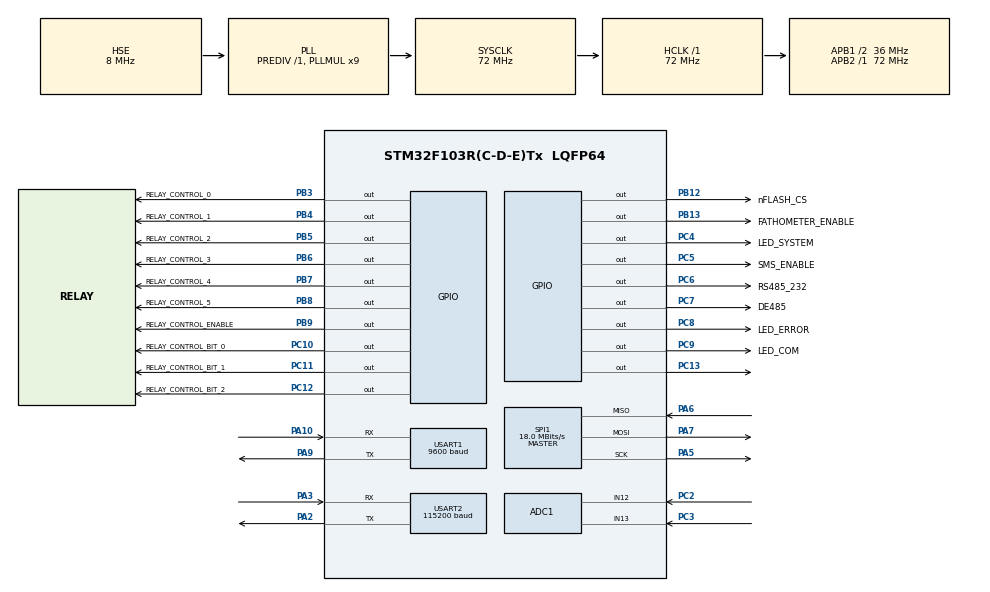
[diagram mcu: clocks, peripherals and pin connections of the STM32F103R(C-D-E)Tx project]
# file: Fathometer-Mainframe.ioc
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ADC1.Channel-0\#ChannelRegularConversion=ADC_CHANNEL_12
ADC1.Channel-1\#ChannelRegularConversion=ADC_CHANNEL_13
ADC1.ContinuousConvMode=ENABLE
ADC1.NbrOfConversion=2
ADC1.NbrOfConversionFlag=1
ADC1.Rank-0\#ChannelRegularConversion=1
ADC1.Rank-1\#ChannelRegularConversion=2
ADC1.SamplingTime-0\#ChannelRegularConversion=ADC_SAMPLETIME_239CYCLES_5
ADC1.SamplingTime-1\#ChannelRegularConversion=ADC_SAMPLETIME_239CYCLES_5
ADC1.master=1
Dma.ADC1.0.Direction=DMA_PERIPH_TO_MEMORY
Dma.ADC1.0.Instance=DMA1_Channel1
Dma.ADC1.0.MemDataAlignment=DMA_MDATAALIGN_HALFWORD
Dma.ADC1.0.MemInc=DMA_MINC_ENABLE
Dma.ADC1.0.Mode=DMA_CIRCULAR
Dma.ADC1.0.PeriphDataAlignment=DMA_PDATAALIGN_HALFWORD
Dma.ADC1.0.PeriphInc=DMA_PINC_DISABLE
Dma.ADC1.0.Priority=DMA_PRIORITY_LOW
Dma.Request0=ADC1
Dma.Request1=SPI1_TX
Dma.Request2=SPI1_RX
Dma.Request3=USART1_RX
Dma.Request4=USART1_TX
Dma.Request5=USART2_RX
Dma.Request6=USART2_TX
Dma.SPI1_RX.2.Direction=DMA_PERIPH_TO_MEMORY
Dma.SPI1_RX.2.Instance=DMA1_Channel2
Dma.SPI1_RX.2.MemDataAlignment=DMA_MDATAALIGN_BYTE
Dma.SPI1_RX.2.MemInc=DMA_MINC_ENABLE
Dma.SPI1_RX.2.Mode=DMA_NORMAL
Dma.SPI1_RX.2.PeriphDataAlignment=DMA_PDATAALIGN_BYTE
Dma.SPI1_RX.2.PeriphInc=DMA_PINC_DISABLE
Dma.SPI1_RX.2.Priority=DMA_PRIORITY_LOW
Dma.SPI1_TX.1.Direction=DMA_MEMORY_TO_PERIPH
Dma.SPI1_TX.1.Instance=DMA1_Channel3
Dma.SPI1_TX.1.MemDataAlignment=DMA_MDATAALIGN_BYTE
Dma.SPI1_TX.1.MemInc=DMA_MINC_ENABLE
Dma.SPI1_TX.1.Mode=DMA_NORMAL
Dma.SPI1_TX.1.PeriphDataAlignment=DMA_PDATAALIGN_BYTE
Dma.SPI1_TX.1.PeriphInc=DMA_PINC_DISABLE
Dma.SPI1_TX.1.Priority=DMA_PRIORITY_LOW
Dma.USART1_RX.3.Direction=DMA_PERIPH_TO_MEMORY
Dma.USART1_RX.3.Instance=DMA1_Channel5
Dma.USART1_RX.3.MemDataAlignment=DMA_MDATAALIGN_BYTE
Dma.USART1_RX.3.MemInc=DMA_MINC_ENABLE
Dma.USART1_RX.3.Mode=DMA_NORMAL
Dma.USART1_RX.3.PeriphDataAlignment=DMA_PDATAALIGN_BYTE
Dma.USART1_RX.3.PeriphInc=DMA_PINC_DISABLE
Dma.USART1_RX.3.Priority=DMA_PRIORITY_HIGH
Dma.USART1_TX.4.Direction=DMA_MEMORY_TO_PERIPH
Dma.USART1_TX.4.Instance=DMA1_Channel4
Dma.USART1_TX.4.MemDataAlignment=DMA_MDATAALIGN_BYTE
Dma.USART1_TX.4.MemInc=DMA_MINC_ENABLE
Dma.USART1_TX.4.Mode=DMA_NORMAL
Dma.USART1_TX.4.PeriphDataAlignment=DMA_PDATAALIGN_BYTE
Dma.USART1_TX.4.PeriphInc=DMA_PINC_DISABLE
Dma.USART1_TX.4.Priority=DMA_PRIORITY_LOW
Dma.USART2_RX.5.Direction=DMA_PERIPH_TO_MEMORY
Dma.USART2_RX.5.Instance=DMA1_Channel6
Dma.USART2_RX.5.MemDataAlignment=DMA_MDATAALIGN_BYTE
Dma.USART2_RX.5.MemInc=DMA_MINC_ENABLE
Dma.USART2_RX.5.Mode=DMA_NORMAL
Dma.USART2_RX.5.PeriphDataAlignment=DMA_PDATAALIGN_BYTE
Dma.USART2_RX.5.PeriphInc=DMA_PINC_DISABLE
Dma.USART2_RX.5.Priority=DMA_PRIORITY_LOW
Dma.USART2_TX.6.Direction=DMA_MEMORY_TO_PERIPH
Dma.USART2_TX.6.Instance=DMA1_Channel7
Dma.USART2_TX.6.MemDataAlignment=DMA_MDATAALIGN_BYTE
Dma.USART2_TX.6.MemInc=DMA_MINC_ENABLE
Dma.USART2_TX.6.Mode=DMA_NORMAL
Dma.USART2_TX.6.PeriphDataAlignment=DMA_PDATAALIGN_BYTE
Dma.USART2_TX.6.PeriphInc=DMA_PINC_DISABLE
Dma.USART2_TX.6.Priority=DMA_PRIORITY_LOW
FREERTOS.Events01=serialCommandEvent,Dynamic,NULL
FREERTOS.Tasks01=mainTask,24,1024,osMainEntry,Default,NULL,Dynamic,NULL,NULL;serialProcess,48,2048,serialCommandProcess,Default,NULL,Dynamic,NULL,NULL
FREERTOS.Timers01=heartbeatTimer,heartbeatCallback,osTimerPeriodic,Default,NULL,Dynamic,NULL
FREERTOS.configTICK_RATE_HZ=100
FREERTOS.configTOTAL_HEAP_SIZE=20480
FREERTOS.configUSE_NEWLIB_REENTRANT=1
IWDG.Prescaler=IWDG_PRESCALER_256
Mcu.Family=STM32F1
Mcu.Name=STM32F103R(C-D-E)Tx
Mcu.Package=LQFP64
NVIC.DMA1_Channel1_IRQn=true\:5\:0\:false\:false\:true\:true\:false\:true\:true
NVIC.DMA1_Channel2_IRQn=true\:5\:0\:false\:false\:true\:true\:false\:true\:true
NVIC.DMA1_Channel3_IRQn=true\:5\:0\:false\:false\:true\:true\:false\:true\:true
NVIC.DMA1_Channel4_IRQn=true\:5\:0\:false\:false\:true\:true\:false\:true\:true
NVIC.DMA1_Channel5_IRQn=true\:5\:0\:false\:false\:true\:true\:false\:true\:true
NVIC.DMA1_Channel6_IRQn=true\:5\:0\:false\:false\:true\:true\:false\:true\:true
NVIC.DMA1_Channel7_IRQn=true\:5\:0\:false\:false\:true\:true\:false\:true\:true
NVIC.PriorityGroup=NVIC_PRIORITYGROUP_4
NVIC.TIM6_IRQn=true\:15\:0\:false\:false\:true\:false\:false\:true\:true
NVIC.TimeBase=TIM6_IRQn
NVIC.TimeBaseIP=TIM6
NVIC.USART1_IRQn=true\:5\:0\:false\:false\:true\:true\:true\:true\:true
NVIC.USART2_IRQn=true\:5\:0\:false\:false\:true\:true\:true\:true\:true
PA10.GPIO_PuPd=GPIO_PULLUP
PA10.Mode=Asynchronous
PA10.Signal=USART1_RX
PA13.Mode=Serial_Wire
PA13.Signal=SYS_JTMS-SWDIO
PA14.Mode=Serial_Wire
PA14.Signal=SYS_JTCK-SWCLK
PA2.Mode=Asynchronous
PA2.Signal=USART2_TX
PA3.GPIO_PuPd=GPIO_PULLUP
PA3.Mode=Asynchronous
PA3.Signal=USART2_RX
PA5.Mode=Full_Duplex_Master
PA5.Signal=SPI1_SCK
PA6.Mode=Full_Duplex_Master
PA6.Signal=SPI1_MISO
PA7.Mode=Full_Duplex_Master
PA7.Signal=SPI1_MOSI
PA9.Mode=Asynchronous
PA9.Signal=USART1_TX
PB12.GPIO_Label=nFLASH_CS
PB12.Signal=GPIO_Output
PB13.GPIO_Label=FATHOMETER_ENABLE
PB13.Signal=GPIO_Output
PB3.GPIO_Label=RELAY_CONTROL_0
PB3.Signal=GPIO_Output
PB4.GPIO_Label=RELAY_CONTROL_1
PB4.Signal=GPIO_Output
PB5.GPIO_Label=RELAY_CONTROL_2
PB5.Signal=GPIO_Output
PB6.GPIO_Label=RELAY_CONTROL_3
PB6.Signal=GPIO_Output
PB7.GPIO_Label=RELAY_CONTROL_4
PB7.Signal=GPIO_Output
PB8.GPIO_Label=RELAY_CONTROL_5
PB8.Signal=GPIO_Output
PB9.GPIO_Label=RELAY_CONTROL_ENABLE
PB9.Signal=GPIO_Output
PC10.GPIO_Label=RELAY_CONTROL_BIT_0
PC10.Signal=GPIO_Output
PC11.GPIO_Label=RELAY_CONTROL_BIT_1
PC11.Signal=GPIO_Output
PC12.GPIO_Label=RELAY_CONTROL_BIT_2
PC12.Signal=GPIO_Output
PC13-TAMPER-RTC.GPIO_PuPd=GPIO_NOPULL
PC13-TAMPER-RTC.Signal=GPIO_Output
PC14-OSC32_IN.Mode=LSE-External-Oscillator
PC14-OSC32_IN.Signal=RCC_OSC32_IN
PC15-OSC32_OUT.Mode=LSE-External-Oscillator
PC15-OSC32_OUT.Signal=RCC_OSC32_OUT
PC2.Signal=ADCx_IN12
PC3.Signal=ADCx_IN13
PC4.GPIO_Label=LED_SYSTEM
PC4.Signal=GPIO_Output
PC5.GPIO_Label=SMS_ENABLE
PC5.Signal=GPIO_Output
PC6.GPIO_Label=RS485_232
PC6.PinState=GPIO_PIN_SET
PC6.Signal=GPIO_Output
PC7.GPIO_Label=DE485
PC7.Signal=GPIO_Output
PC8.GPIO_Label=LED_ERROR
PC8.Signal=GPIO_Output
PC9.GPIO_Label=LED_COM
PC9.Signal=GPIO_Output
PD0-OSC_IN.Mode=HSE-External-Oscillator
PD0-OSC_IN.Signal=RCC_OSC_IN
PD1-OSC_OUT.Mode=HSE-External-Oscillator
PD1-OSC_OUT.Signal=RCC_OSC_OUT
ProjectManager.HeapSize=0x200
ProjectManager.StackSize=0x400
ProjectManager.TargetToolchain=STM32CubeIDE
RCC.ADCPresc=RCC_ADCPCLK2_DIV6
RCC.AHBFreq_Value=72000000
RCC.APB1CLKDivider=RCC_HCLK_DIV2
RCC.APB1Freq_Value=36000000
RCC.APB1TimFreq_Value=72000000
RCC.APB2Freq_Value=72000000
RCC.APB2TimFreq_Value=72000000
RCC.HCLKFreq_Value=72000000
RCC.PLLMUL=RCC_PLL_MUL9
RCC.PLLSourceVirtual=RCC_PLLSOURCE_HSE
RCC.RTCClockSelection=RCC_RTCCLKSOURCE_LSE
RCC.SYSCLKFreq_VALUE=72000000
RCC.SYSCLKSource=RCC_SYSCLKSOURCE_PLLCLK
RCC.USBFreq_Value=72000000
RTC.Year=23
SH.ADCx_IN12.0=ADC1_IN12,IN12
SH.ADCx_IN13.0=ADC1_IN13,IN13
SPI1.BaudRatePrescaler=SPI_BAUDRATEPRESCALER_4
SPI1.CalculateBaudRate=18.0 MBits/s
SPI1.Direction=SPI_DIRECTION_2LINES
SPI1.Mode=SPI_MODE_MASTER
SPI1.VirtualType=VM_MASTER
USART1.BaudRate=9600
USART1.VirtualMode=VM_ASYNC
USART2.BaudRate=115200
USART2.VirtualMode=VM_ASYNC
VP_CRC_VS_CRC.Mode=CRC_Activate
VP_FREERTOS_VS_CMSIS_V2.Mode=CMSIS_V2
VP_IWDG_VS_IWDG.Mode=IWDG_Activate
VP_RTC_VS_RTC_Activate.Mode=RTC_Enabled
VP_RTC_VS_RTC_Calendar.Mode=RTC_Calendar
VP_SYS_VS_tim6.Mode=TIM6
board=custom

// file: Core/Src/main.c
/* USER CODE BEGIN Header */
/**
  ******************************************************************************
  * @file           : main.c
  * @brief          : Main program body
  ******************************************************************************
  * @attention
  *
  * Copyright (c) 2022 STMicroelectronics.
  * All rights reserved.
  *
  * This software is licensed under terms that can be found in the LICENSE file
  * in the root directory of this software component.
  * If no LICENSE file comes with this software, it is provided AS-IS.
  *
  ******************************************************************************
  */
/* USER CODE END Header */
#include "main.h"
#include "cmsis_os.h"
#include "adc.h"
#include "crc.h"
#include "dma.h"
#include "iwdg.h"
#include "rtc.h"
#include "spi.h"
#include "usart.h"
#include "gpio.h"

void SystemClock_Config(void);
void MX_FREERTOS_Init(void);

int main(void)
{

  /* MCU Configuration--------------------------------------------------------*/

  /* Reset of all peripherals, Initializes the Flash interface and the Systick. */
  HAL_Init();

  /* Configure the system clock */
  SystemClock_Config();

  /* Initialize all configured peripherals */
  MX_GPIO_Init();
  MX_DMA_Init();
  MX_RTC_Init();
  MX_ADC1_Init();
  MX_USART1_UART_Init();
  MX_USART2_UART_Init();
  MX_SPI1_Init();
  MX_CRC_Init();
  MX_IWDG_Init();

  /* Init scheduler */
  osKernelInitialize();  /* Call init function for freertos objects (in freertos.c) */
  MX_FREERTOS_Init();

  /* Start scheduler */
  osKernelStart();

  /* We should never get here as control is now taken by the scheduler */
  /* Infinite loop */
  while (1)
  {

  }
}

void SystemClock_Config(void)
{
  RCC_OscInitTypeDef RCC_OscInitStruct = {0};
  RCC_ClkInitTypeDef RCC_ClkInitStruct = {0};
  RCC_PeriphCLKInitTypeDef PeriphClkInit = {0};

  /** Initializes the RCC Oscillators according to the specified parameters
  * in the RCC_OscInitTypeDef structure.
  */
  RCC_OscInitStruct.OscillatorType = RCC_OSCILLATORTYPE_LSI|RCC_OSCILLATORTYPE_HSE
                              |RCC_OSCILLATORTYPE_LSE;
  RCC_OscInitStruct.HSEState = RCC_HSE_ON;
  RCC_OscInitStruct.HSEPredivValue = RCC_HSE_PREDIV_DIV1;
  RCC_OscInitStruct.LSEState = RCC_LSE_ON;
  RCC_OscInitStruct.HSIState = RCC_HSI_ON;
  RCC_OscInitStruct.LSIState = RCC_LSI_ON;
  RCC_OscInitStruct.PLL.PLLState = RCC_PLL_ON;
  RCC_OscInitStruct.PLL.PLLSource = RCC_PLLSOURCE_HSE;
  RCC_OscInitStruct.PLL.PLLMUL = RCC_PLL_MUL9;
  if (HAL_RCC_OscConfig(&RCC_OscInitStruct) != HAL_OK)
  {
    Error_Handler();
  }

  /** Initializes the CPU, AHB and APB buses clocks
  */
  RCC_ClkInitStruct.ClockType = RCC_CLOCKTYPE_HCLK|RCC_CLOCKTYPE_SYSCLK
                              |RCC_CLOCKTYPE_PCLK1|RCC_CLOCKTYPE_PCLK2;
  RCC_ClkInitStruct.SYSCLKSource = RCC_SYSCLKSOURCE_PLLCLK;
  RCC_ClkInitStruct.AHBCLKDivider = RCC_SYSCLK_DIV1;
  RCC_ClkInitStruct.APB1CLKDivider = RCC_HCLK_DIV2;
  RCC_ClkInitStruct.APB2CLKDivider = RCC_HCLK_DIV1;

  if (HAL_RCC_ClockConfig(&RCC_ClkInitStruct, FLASH_LATENCY_2) != HAL_OK)
  {
    Error_Handler();
  }
  PeriphClkInit.PeriphClockSelection = RCC_PERIPHCLK_RTC|RCC_PERIPHCLK_ADC;
  PeriphClkInit.RTCClockSelection = RCC_RTCCLKSOURCE_LSE;
  PeriphClkInit.AdcClockSelection = RCC_ADCPCLK2_DIV6;
  if (HAL_RCCEx_PeriphCLKConfig(&PeriphClkInit) != HAL_OK)
  {
    Error_Handler();
  }
}

void HAL_TIM_PeriodElapsedCallback(TIM_HandleTypeDef *htim)
{
  if (htim->Instance == TIM6) {
    HAL_IncTick();
  }
}

void Error_Handler(void)
{
  __disable_irq();
  while (1)
  {
  }
}

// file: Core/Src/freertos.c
/* USER CODE BEGIN Header */
/**
  ******************************************************************************
  * File Name          : freertos.c
  * Description        : Code for freertos applications
  ******************************************************************************
  * @attention
  *
  * Copyright (c) 2022 STMicroelectronics.
  * All rights reserved.
  *
  * This software is licensed under terms that can be found in the LICENSE file
  * in the root directory of this software component.
  * If no LICENSE file comes with this software, it is provided AS-IS.
  *
  ******************************************************************************
  */
/* USER CODE END Header */

#include "FreeRTOS.h"
#include "task.h"
#include "main.h"
#include "cmsis_os.h"

/* USER CODE BEGIN Includes */
#include "serial_feedback_define.h"
#include "flash.h"
/* USER CODE END Includes */

/* USER CODE BEGIN PTD */
union G_FLASH_DS {
    int intAccess[0x400];
    float floatAccess[0x400];
    uint32_t wordAccess[0x400];
    uint8_t byteAccess[0x1000];
};
union G_TASK_DS {
    int intAccess[13];
    float floatAccess[13];
    uint32_t wordAccess[13];
    uint8_t byteAccess[52];
};
/* USER CODE END PTD */

/* USER CODE BEGIN PD */
extern IWDG_HandleTypeDef hiwdg;
extern UART_HandleTypeDef huart1;
extern UART_HandleTypeDef huart2;
extern DMA_HandleTypeDef hdma_usart1_rx;
extern DMA_HandleTypeDef hdma_usart2_rx;
extern ADC_HandleTypeDef hadc1;
extern DMA_HandleTypeDef hdma_adc1;
extern RTC_HandleTypeDef hrtc;
extern CRC_HandleTypeDef hcrc;
/* USER CODE END PD */

/* USER CODE BEGIN PM */
#define RX_BUFFER_SIZE          100
#define RX_MAIN_BUFFER_SIZE     200

/* StatusReg flag define */
#define modeFlagA               31
#define modeFlagTransparent     30
#define ippFlag                 29
#define taskFlag                28
#define fathometerStatFlag1     27
#define fathometerStatFlag2     26
#define fathometerStatFlag3     25
#define fathometerStatFlag4     24
#define fathometerStatFlag5     23
#define fathometerStatFlag6     22
#define fathometerDataReadyFlag 21
#define flashDataPointerFlag    20
#define uplinkTimeoutFlag       19
#define maintenanceFlag         17
#define voltageFlag             16

/* Config address define */
#define SERIAL_NUMBER_ADDR      0x0807F000
#define BAUD_RATE_ADDR          0x0807E800
#define DFU_FLAG_ADDR           0x0807E000
#define RTC_INIT_FLAG_ADDR      0x0807D800
#define RTC_INIT_FLAG_DATA      0x04020D0A

SYSTEM_RESET_PROTOTYPE {
    HAL_Delay(600);
    __ASM volatile ("cpsid i");
    HAL_NVIC_SystemReset();
}

WRITE_FLASH_PROTOTYPE {
    if (address >= FLASH_START_ADDRESS && address <= FLASH_END_ADDRESS) {
        HAL_FLASH_Unlock();
        HAL_FLASH_Program(FLASH_TYPEPROGRAM_WORD, address, data);
        HAL_FLASH_Lock();
    }
}

ERASE_FLASH_PROTOTYPE {
    int sect = 0;
    uint32_t PageError = 0;
    if (address >= FLASH_START_ADDRESS || address >= FLASH_END_ADDRESS) {
        while (address >= FLASH_START_ADDRESS + FLASH_PAGE_SIZE) {
            sect++;
            address -= FLASH_PAGE_SIZE;
        }
        FLASH_EraseInitTypeDef EraseInitStruct;
        EraseInitStruct.TypeErase = FLASH_TYPEERASE_PAGES;
        EraseInitStruct.NbPages = 1;
        EraseInitStruct.PageAddress = FLASH_START_ADDRESS + sect * FLASH_PAGE_SIZE;
        HAL_FLASH_Unlock();
        __HAL_FLASH_CLEAR_FLAG(FLASH_FLAG_BSY | FLASH_FLAG_EOP | FLASH_FLAG_WRPERR | FLASH_SR_PGERR);
        HAL_FLASHEx_Erase(&EraseInitStruct, &PageError);
        HAL_FLASH_Lock();
    }
}

SN_PRINT_PROTOTYPE {
    uint32_t firstWord = G_READ_FLASH(SERIAL_NUMBER_ADDR);
    uint32_t secondWord = G_READ_FLASH(SERIAL_NUMBER_ADDR + WORD_SIZE);

    if (firstWord == DEFAULT_FLASH && secondWord == DEFAULT_FLASH) {
        printf(SERIAL_FEEDBACK_ERROR_GET_SERIAL_NUMBER_NOT_SET);
    } else {
        char serialNum[9] = {};
        serialNum[8] = '\0';
        int shift = 32;
        for (int i = 0; i < 4; i++) {
            serialNum[i] = (firstWord >> (shift -= 8)) & 0xFF;
            serialNum[i + 4] = (secondWord >> (shift)) & 0xFF;
        }
        if (loc == 1) {
            printf(SERIAL_FEEDBACK_INFO_GET_SERIAL_NUMBER, serialNum);
        } else {
            printf(SERIAL_FEEDBACK_INFO_GET_SERIAL_NUMBER_INITIAL, serialNum);
        }

    }
}

SMS_REFRESH_PROTOTYPE {
    switch (status) {
        case 1: {
            HAL_GPIO_WritePin(RELAY_CONTROL_BIT_0_GPIO_Port, RELAY_CONTROL_BIT_0_Pin, GPIO_PIN_RESET);
            HAL_GPIO_WritePin(RELAY_CONTROL_BIT_1_GPIO_Port, RELAY_CONTROL_BIT_1_Pin, GPIO_PIN_RESET);
            HAL_GPIO_WritePin(RELAY_CONTROL_BIT_2_GPIO_Port, RELAY_CONTROL_BIT_2_Pin, GPIO_PIN_RESET);
            break;
        }
        case 2: {
            HAL_GPIO_WritePin(RELAY_CONTROL_BIT_0_GPIO_Port, RELAY_CONTROL_BIT_0_Pin, GPIO_PIN_SET);
            HAL_GPIO_WritePin(RELAY_CONTROL_BIT_1_GPIO_Port, RELAY_CONTROL_BIT_1_Pin, GPIO_PIN_RESET);
            HAL_GPIO_WritePin(RELAY_CONTROL_BIT_2_GPIO_Port, RELAY_CONTROL_BIT_2_Pin, GPIO_PIN_RESET);
            break;
        }
        case 3: {
            HAL_GPIO_WritePin(RELAY_CONTROL_BIT_0_GPIO_Port, RELAY_CONTROL_BIT_0_Pin, GPIO_PIN_RESET);
            HAL_GPIO_WritePin(RELAY_CONTROL_BIT_1_GPIO_Port, RELAY_CONTROL_BIT_1_Pin, GPIO_PIN_SET);
            HAL_GPIO_WritePin(RELAY_CONTROL_BIT_2_GPIO_Port, RELAY_CONTROL_BIT_2_Pin, GPIO_PIN_RESET);
            break;
        }
        case 4: {
            HAL_GPIO_WritePin(RELAY_CONTROL_BIT_0_GPIO_Port, RELAY_CONTROL_BIT_0_Pin, GPIO_PIN_SET);
            HAL_GPIO_WritePin(RELAY_CONTROL_BIT_1_GPIO_Port, RELAY_CONTROL_BIT_1_Pin, GPIO_PIN_SET);
            HAL_GPIO_WritePin(RELAY_CONTROL_BIT_2_GPIO_Port, RELAY_CONTROL_BIT_2_Pin, GPIO_PIN_RESET);
            break;
        }
        case 5: {
            HAL_GPIO_WritePin(RELAY_CONTROL_BIT_0_GPIO_Port, RELAY_CONTROL_BIT_0_Pin, GPIO_PIN_RESET);
            HAL_GPIO_WritePin(RELAY_CONTROL_BIT_1_GPIO_Port, RELAY_CONTROL_BIT_1_Pin, GPIO_PIN_RESET);
            HAL_GPIO_WritePin(RELAY_CONTROL_BIT_2_GPIO_Port, RELAY_CONTROL_BIT_2_Pin, GPIO_PIN_SET);
            break;
        }
        case 6: {
            HAL_GPIO_WritePin(RELAY_CONTROL_BIT_0_GPIO_Port, RELAY_CONTROL_BIT_0_Pin, GPIO_PIN_SET);
            HAL_GPIO_WritePin(RELAY_CONTROL_BIT_1_GPIO_Port, RELAY_CONTROL_BIT_1_Pin, GPIO_PIN_RESET);
            HAL_GPIO_WritePin(RELAY_CONTROL_BIT_2_GPIO_Port, RELAY_CONTROL_BIT_2_Pin, GPIO_PIN_SET);
            break;
        }
        case 7: {
            HAL_GPIO_WritePin(RELAY_CONTROL_BIT_0_GPIO_Port, RELAY_CONTROL_BIT_0_Pin, GPIO_PIN_RESET);
            HAL_GPIO_WritePin(RELAY_CONTROL_BIT_1_GPIO_Port, RELAY_CONTROL_BIT_1_Pin, GPIO_PIN_SET);
            HAL_GPIO_WritePin(RELAY_CONTROL_BIT_2_GPIO_Port, RELAY_CONTROL_BIT_2_Pin, GPIO_PIN_SET);
            break;
        }
        case 8: {
            HAL_GPIO_WritePin(RELAY_CONTROL_BIT_0_GPIO_Port, RELAY_CONTROL_BIT_0_Pin, GPIO_PIN_SET);
            HAL_GPIO_WritePin(RELAY_CONTROL_BIT_1_GPIO_Port, RELAY_CONTROL_BIT_1_Pin, GPIO_PIN_SET);
            HAL_GPIO_WritePin(RELAY_CONTROL_BIT_2_GPIO_Port, RELAY_CONTROL_BIT_2_Pin, GPIO_PIN_SET);
            break;
        }
        default: {
            HAL_GPIO_WritePin(RELAY_CONTROL_BIT_0_GPIO_Port, RELAY_CONTROL_BIT_0_Pin, GPIO_PIN_SET);
            HAL_GPIO_WritePin(RELAY_CONTROL_BIT_1_GPIO_Port, RELAY_CONTROL_BIT_1_Pin, GPIO_PIN_SET);
            HAL_GPIO_WritePin(RELAY_CONTROL_BIT_2_GPIO_Port, RELAY_CONTROL_BIT_2_Pin, GPIO_PIN_SET);
        }
    }
    HAL_GPIO_WritePin(SMS_ENABLE_GPIO_Port, SMS_ENABLE_Pin, GPIO_PIN_SET);
    HAL_GPIO_WritePin(SMS_ENABLE_GPIO_Port, SMS_ENABLE_Pin, GPIO_PIN_RESET);
}

RELAY_CONTROL_REFRESH_PROTOTYPE {
    switch (status) {
        case 1: {
            HAL_GPIO_WritePin(RELAY_CONTROL_BIT_0_GPIO_Port, RELAY_CONTROL_BIT_0_Pin, GPIO_PIN_RESET);
            HAL_GPIO_WritePin(RELAY_CONTROL_BIT_1_GPIO_Port, RELAY_CONTROL_BIT_1_Pin, GPIO_PIN_RESET);
            HAL_GPIO_WritePin(RELAY_CONTROL_BIT_2_GPIO_Port, RELAY_CONTROL_BIT_2_Pin, GPIO_PIN_RESET);
            HAL_GPIO_WritePin(RELAY_CONTROL_0_GPIO_Port, RELAY_CONTROL_0_Pin, GPIO_PIN_SET);
            HAL_GPIO_WritePin(RELAY_CONTROL_1_GPIO_Port, RELAY_CONTROL_1_Pin, GPIO_PIN_RESET);
            HAL_GPIO_WritePin(RELAY_CONTROL_2_GPIO_Port, RELAY_CONTROL_2_Pin, GPIO_PIN_RESET);
            HAL_GPIO_WritePin(RELAY_CONTROL_3_GPIO_Port, RELAY_CONTROL_3_Pin, GPIO_PIN_RESET);
            HAL_GPIO_WritePin(RELAY_CONTROL_4_GPIO_Port, RELAY_CONTROL_4_Pin, GPIO_PIN_RESET);
            HAL_GPIO_WritePin(RELAY_CONTROL_5_GPIO_Port, RELAY_CONTROL_5_Pin, GPIO_PIN_RESET);
            break;
        }
        case 2: {
            HAL_GPIO_WritePin(RELAY_CONTROL_BIT_0_GPIO_Port, RELAY_CONTROL_BIT_0_Pin, GPIO_PIN_SET);
            HAL_GPIO_WritePin(RELAY_CONTROL_BIT_1_GPIO_Port, RELAY_CONTROL_BIT_1_Pin, GPIO_PIN_RESET);
            HAL_GPIO_WritePin(RELAY_CONTROL_BIT_2_GPIO_Port, RELAY_CONTROL_BIT_2_Pin, GPIO_PIN_RESET);
            HAL_GPIO_WritePin(RELAY_CONTROL_0_GPIO_Port, RELAY_CONTROL_0_Pin, GPIO_PIN_RESET);
            HAL_GPIO_WritePin(RELAY_CONTROL_1_GPIO_Port, RELAY_CONTROL_1_Pin, GPIO_PIN_SET);
            HAL_GPIO_WritePin(RELAY_CONTROL_2_GPIO_Port, RELAY_CONTROL_2_Pin, GPIO_PIN_RESET);
            HAL_GPIO_WritePin(RELAY_CONTROL_3_GPIO_Port, RELAY_CONTROL_3_Pin, GPIO_PIN_RESET);
            HAL_GPIO_WritePin(RELAY_CONTROL_4_GPIO_Port, RELAY_CONTROL_4_Pin, GPIO_PIN_RESET);
            HAL_GPIO_WritePin(RELAY_CONTROL_5_GPIO_Port, RELAY_CONTROL_5_Pin, GPIO_PIN_RESET);
            break;
        }
        case 3: {
            HAL_GPIO_WritePin(RELAY_CONTROL_BIT_0_GPIO_Port, RELAY_CONTROL_BIT_0_Pin, GPIO_PIN_RESET);
            HAL_GPIO_WritePin(RELAY_CONTROL_BIT_1_GPIO_Port, RELAY_CONTROL_BIT_1_Pin, GPIO_PIN_SET);
            HAL_GPIO_WritePin(RELAY_CONTROL_BIT_2_GPIO_Port, RELAY_CONTROL_BIT_2_Pin, GPIO_PIN_RESET);
            HAL_GPIO_WritePin(RELAY_CONTROL_0_GPIO_Port, RELAY_CONTROL_0_Pin, GPIO_PIN_RESET);
            HAL_GPIO_WritePin(RELAY_CONTROL_1_GPIO_Port, RELAY_CONTROL_1_Pin, GPIO_PIN_RESET);
            HAL_GPIO_WritePin(RELAY_CONTROL_2_GPIO_Port, RELAY_CONTROL_2_Pin, GPIO_PIN_SET);
            HAL_GPIO_WritePin(RELAY_CONTROL_3_GPIO_Port, RELAY_CONTROL_3_Pin, GPIO_PIN_RESET);
            HAL_GPIO_WritePin(RELAY_CONTROL_4_GPIO_Port, RELAY_CONTROL_4_Pin, GPIO_PIN_RESET);
            HAL_GPIO_WritePin(RELAY_CONTROL_5_GPIO_Port, RELAY_CONTROL_5_Pin, GPIO_PIN_RESET);
            break;
        }
        case 4: {
            HAL_GPIO_WritePin(RELAY_CONTROL_BIT_0_GPIO_Port, RELAY_CONTROL_BIT_0_Pin, GPIO_PIN_SET);
            HAL_GPIO_WritePin(RELAY_CONTROL_BIT_1_GPIO_Port, RELAY_CONTROL_BIT_1_Pin, GPIO_PIN_SET);
            HAL_GPIO_WritePin(RELAY_CONTROL_BIT_2_GPIO_Port, RELAY_CONTROL_BIT_2_Pin, GPIO_PIN_RESET);
            HAL_GPIO_WritePin(RELAY_CONTROL_0_GPIO_Port, RELAY_CONTROL_0_Pin, GPIO_PIN_RESET);
            HAL_GPIO_WritePin(RELAY_CONTROL_1_GPIO_Port, RELAY_CONTROL_1_Pin, GPIO_PIN_RESET);
            HAL_GPIO_WritePin(RELAY_CONTROL_2_GPIO_Port, RELAY_CONTROL_2_Pin, GPIO_PIN_RESET);
            HAL_GPIO_WritePin(RELAY_CONTROL_3_GPIO_Port, RELAY_CONTROL_3_Pin, GPIO_PIN_SET);
            HAL_GPIO_WritePin(RELAY_CONTROL_4_GPIO_Port, RELAY_CONTROL_4_Pin, GPIO_PIN_RESET);
            HAL_GPIO_WritePin(RELAY_CONTROL_5_GPIO_Port, RELAY_CONTROL_5_Pin, GPIO_PIN_RESET);
            break;
        }
        case 5: {
            HAL_GPIO_WritePin(RELAY_CONTROL_BIT_0_GPIO_Port, RELAY_CONTROL_BIT_0_Pin, GPIO_PIN_RESET);
            HAL_GPIO_WritePin(RELAY_CONTROL_BIT_1_GPIO_Port, RELAY_CONTROL_BIT_1_Pin, GPIO_PIN_RESET);
            HAL_GPIO_WritePin(RELAY_CONTROL_BIT_2_GPIO_Port, RELAY_CONTROL_BIT_2_Pin, GPIO_PIN_SET);
            HAL_GPIO_WritePin(RELAY_CONTROL_0_GPIO_Port, RELAY_CONTROL_0_Pin, GPIO_PIN_RESET);
            HAL_GPIO_WritePin(RELAY_CONTROL_1_GPIO_Port, RELAY_CONTROL_1_Pin, GPIO_PIN_RESET);
            HAL_GPIO_WritePin(RELAY_CONTROL_2_GPIO_Port, RELAY_CONTROL_2_Pin, GPIO_PIN_RESET);
            HAL_GPIO_WritePin(RELAY_CONTROL_3_GPIO_Port, RELAY_CONTROL_3_Pin, GPIO_PIN_RESET);
            HAL_GPIO_WritePin(RELAY_CONTROL_4_GPIO_Port, RELAY_CONTROL_4_Pin, GPIO_PIN_SET);
            HAL_GPIO_WritePin(RELAY_CONTROL_5_GPIO_Port, RELAY_CONTROL_5_Pin, GPIO_PIN_RESET);
            break;
        }
        case 6: {
            HAL_GPIO_WritePin(RELAY_CONTROL_BIT_0_GPIO_Port, RELAY_CONTROL_BIT_0_Pin, GPIO_PIN_SET);
            HAL_GPIO_WritePin(RELAY_CONTROL_BIT_1_GPIO_Port, RELAY_CONTROL_BIT_1_Pin, GPIO_PIN_RESET);
            HAL_GPIO_WritePin(RELAY_CONTROL_BIT_2_GPIO_Port, RELAY_CONTROL_BIT_2_Pin, GPIO_PIN_SET);
            HAL_GPIO_WritePin(RELAY_CONTROL_0_GPIO_Port, RELAY_CONTROL_0_Pin, GPIO_PIN_RESET);
            HAL_GPIO_WritePin(RELAY_CONTROL_1_GPIO_Port, RELAY_CONTROL_1_Pin, GPIO_PIN_RESET);
            HAL_GPIO_WritePin(RELAY_CONTROL_2_GPIO_Port, RELAY_CONTROL_2_Pin, GPIO_PIN_RESET);
            HAL_GPIO_WritePin(RELAY_CONTROL_3_GPIO_Port, RELAY_CONTROL_3_Pin, GPIO_PIN_RESET);
            HAL_GPIO_WritePin(RELAY_CONTROL_4_GPIO_Port, RELAY_CONTROL_4_Pin, GPIO_PIN_RESET);
            HAL_GPIO_WritePin(RELAY_CONTROL_5_GPIO_Port, RELAY_CONTROL_5_Pin, GPIO_PIN_SET);
            break;
        }
        default: {
            HAL_GPIO_WritePin(RELAY_CONTROL_BIT_0_GPIO_Port, RELAY_CONTROL_BIT_0_Pin, GPIO_PIN_SET);
            HAL_GPIO_WritePin(RELAY_CONTROL_BIT_1_GPIO_Port, RELAY_CONTROL_BIT_1_Pin, GPIO_PIN_SET);
            HAL_GPIO_WritePin(RELAY_CONTROL_BIT_2_GPIO_Port, RELAY_CONTROL_BIT_2_Pin, GPIO_PIN_SET);
            HAL_GPIO_WritePin(RELAY_CONTROL_0_GPIO_Port, RELAY_CONTROL_0_Pin, GPIO_PIN_RESET);
            HAL_GPIO_WritePin(RELAY_CONTROL_1_GPIO_Port, RELAY_CONTROL_1_Pin, GPIO_PIN_RESET);
            HAL_GPIO_WritePin(RELAY_CONTROL_2_GPIO_Port, RELAY_CONTROL_2_Pin, GPIO_PIN_RESET);
            HAL_GPIO_WritePin(RELAY_CONTROL_3_GPIO_Port, RELAY_CONTROL_3_Pin, GPIO_PIN_RESET);
            HAL_GPIO_WritePin(RELAY_CONTROL_4_GPIO_Port, RELAY_CONTROL_4_Pin, GPIO_PIN_RESET);
            HAL_GPIO_WritePin(RELAY_CONTROL_5_GPIO_Port, RELAY_CONTROL_5_Pin, GPIO_PIN_RESET);
        }
    }
    HAL_GPIO_WritePin(RELAY_CONTROL_ENABLE_GPIO_Port, RELAY_CONTROL_ENABLE_Pin, GPIO_PIN_SET);
    HAL_GPIO_WritePin(RELAY_CONTROL_ENABLE_GPIO_Port, RELAY_CONTROL_ENABLE_Pin, GPIO_PIN_RESET);
}

//CONTROL_COMMAND_SEND_PROTOTYPE {
////    HAL_UART_DMAStop(&huart1);
//    uint8_t test[10] = {'1', '$', 'R', 'u', 'n', '=', '1', '\r', '\n', '1'};
//    HAL_GPIO_WritePin(DE485_GPIO_Port, DE485_Pin, GPIO_PIN_SET);
//    osDelay(1);
//    HAL_UART_Transmit(&huart1, (uint8_t *) &test, 10, 5);
//    osDelay(1);
//    HAL_GPIO_WritePin(DE485_GPIO_Port, DE485_Pin, GPIO_PIN_RESET);
////    while (HAL_UARTEx_ReceiveToIdle_DMA(&huart1, RxBufferSlave, RX_BUFFER_SIZE) != HAL_OK);
////    __HAL_DMA_DISABLE_IT(&hdma_usart1_rx, DMA_IT_HT);
//}

/* USER CODE END PM */

/* USER CODE BEGIN Variables */
uint32_t statusReg = DEFAULT_FLASH;
uint32_t SERIAL_EVENT_FLAG = 1;
RTC_DateTypeDef currentDate;
RTC_TimeTypeDef currentTime;
uint8_t RxBuffer[RX_BUFFER_SIZE];
uint8_t RxBufferSlave[RX_BUFFER_SIZE];
uint8_t RxMainBuffer[RX_MAIN_BUFFER_SIZE];
uint8_t RxMainBufferSlave[RX_MAIN_BUFFER_SIZE];
uint32_t UID[3];
uint16_t AD_DMA_BUFFER[2] = {0};
float taskDepthBuffer[6][20] = {0};
int taskCountBuffer[6] = {0};
int currentChannel = 1;
int taskTickCount = 0;
union G_FLASH_DS flashDataStruct;
union G_TASK_DS taskDataStruct;
int flashDataPointerStart;
int flashDataPointerEnd;
int debugFlag = 0;

/* USER CODE END Variables */
/* Definitions for mainTask */
osThreadId_t mainTaskHandle;
const osThreadAttr_t mainTask_attributes = {
        .name = "mainTask",
        .stack_size = 1024 * 4,
        .priority = (osPriority_t) osPriorityNormal,
};
/* Definitions for serialProcess */
osThreadId_t serialProcessHandle;
const osThreadAttr_t serialProcess_attributes = {
        .name = "serialProcess",
        .stack_size = 2048 * 4,
        .priority = (osPriority_t) osPriorityRealtime,
};
/* Definitions for heartbeatTimer */
osTimerId_t heartbeatTimerHandle;
const osTimerAttr_t heartbeatTimer_attributes = {
        .name = "heartbeatTimer"
};
/* Definitions for serialCommandEvent */
osEventFlagsId_t serialCommandEventHandle;
const osEventFlagsAttr_t serialCommandEvent_attributes = {
        .name = "serialCommandEvent"
};

/* USER CODE BEGIN FunctionPrototypes */
void readUniqueID(volatile uint32_t *IDArrayPtr);

void intellectualPropertyProtection(void);

void intellectualPropertyProtectionSet(void);

void peripheralInit(void);

void getFlashDPTR(void);

void setFlashDPTR(int start, int end);

void G_CONTROL_COMMAND_SEND(void);
/* USER CODE END FunctionPrototypes */

void osMainEntry(void *argument);

void serialCommandProcess(void *argument);

void heartbeatCallback(void *argument);

void MX_FREERTOS_Init(void); /* (MISRA C 2004 rule 8.1) */

void MX_FREERTOS_Init(void) {
    /* USER CODE BEGIN Init */
    printf(SERIAL_FEEDBACK_INFO_SYSTEM_INIT);
    /* USER CODE END Init */

    /* Create the timer(s) */
    /* creation of heartbeatTimer */
    heartbeatTimerHandle = osTimerNew(heartbeatCallback, osTimerPeriodic, NULL, &heartbeatTimer_attributes);

    /* Create the thread(s) */
    /* creation of mainTask */
    mainTaskHandle = osThreadNew(osMainEntry, NULL, &mainTask_attributes);

    /* creation of serialProcess */
    serialProcessHandle = osThreadNew(serialCommandProcess, NULL, &serialProcess_attributes);

    /* Create the event(s) */
    /* creation of serialCommandEvent */
    serialCommandEventHandle = osEventFlagsNew(&serialCommandEvent_attributes);

}

void osMainEntry(void *argument) {
    /* USER CODE BEGIN osMainEntry */
    UNUSED(argument);

    osTimerStart(heartbeatTimerHandle, 100);

    intellectualPropertyProtection();

    peripheralInit();

    /* Infinite loop */
    for (;;) {

        osDelay(1000);
        vTaskSuspendAll();
        if ((flashDataPointerStart == flashDataPointerEnd) && (flashDataPointerStart > 600)) {
            setFlashDPTR(0, 0);
            getFlashDPTR();
        }
        xTaskResumeAll();
        if (GET_MAIN_VOLTAGE(AD_DMA_BUFFER[0]) > 24.5 || GET_MAIN_VOLTAGE(AD_DMA_BUFFER[0]) < 23.5) {
            G_SET_BIT(statusReg, voltageFlag);
        }
        if (BCD_TO_DECIMAL(currentTime.Hours) == 1 && BCD_TO_DECIMAL(currentTime.Minutes) == 45 &&
            BCD_TO_DECIMAL(currentTime.Seconds) <= 20) {
            if (G_GET_BIT(statusReg, taskFlag) == 1) {
                G_SYSTEM_RESET();
            }
        }

    }
    /* USER CODE END osMainEntry */
}

void serialCommandProcess(void *argument) {
    /* USER CODE BEGIN serialCommandProcess */
    UNUSED(argument);
    uint32_t flags;
    /* Infinite loop */
    for (;;) {
        /* Infinite loop */
        flags = osEventFlagsWait(serialCommandEventHandle, SERIAL_EVENT_FLAG, osFlagsWaitAll, osWaitForever);
        if (flags == SERIAL_EVENT_FLAG) {
            osDelay(1);
            switch (RxMainBuffer[2]) {
                case 'I': {
                    getFlashDPTR();
                    printf(SERIAL_FEEDBACK_INFO_QUERY_STATUS, statusReg,
                           flashDataPointerEnd - flashDataPointerStart,
                           GET_SYSTEM_VOLTAGE(AD_DMA_BUFFER[1]), GET_MAIN_VOLTAGE(AD_DMA_BUFFER[0]));
                    break;
                }
                case 'M': {
                    switch (RxMainBuffer[3]) {
                        case '0':
                            G_CLEAR_BIT(statusReg, modeFlagA);
                            G_SET_BIT(statusReg, modeFlagTransparent);
                            printf(SERIAL_FEEDBACK_INFO_SWITCH_OPERATING_MODE, RxMainBuffer[3]);
                            break;
                        case '1':
                            G_SET_BIT(statusReg, modeFlagA);
                            G_CLEAR_BIT(statusReg, modeFlagTransparent);
                            printf(SERIAL_FEEDBACK_INFO_SWITCH_OPERATING_MODE, RxMainBuffer[3]);
                            break;
                        case '2':
                            G_SET_BIT(statusReg, modeFlagA);
                            G_CLEAR_BIT(statusReg, modeFlagTransparent);
                            printf(SERIAL_FEEDBACK_INFO_SWITCH_OPERATING_MODE, RxMainBuffer[3]);
                            break;
                        case '3':
                            G_SET_BIT(statusReg, modeFlagA);
                            G_CLEAR_BIT(statusReg, modeFlagTransparent);
                            printf(SERIAL_FEEDBACK_INFO_SWITCH_OPERATING_MODE, RxMainBuffer[3]);
                            break;
                        default:
                            printf(SERIAL_FEEDBACK_ERROR_OPERATING_MODE_INVALID);
                    }
                    break;
                }
                case 'R': {
                    printf(SERIAL_FEEDBACK_INFO_SYSTEM_RESTART_PROCEED);
                    G_SYSTEM_RESET();
                    break;
                }
                case 's': {
                    G_SN_PRINT(1);
                    break;
                }
                case 'S': {
                    char snNew[8];
                    int stdFlag = 0;
                    for (int i = 0; i < 8; ++i) {
                        if (CHAR_ASCII_CRITERION(RxMainBuffer[3 + i])) {
                            snNew[7 - i] = RxMainBuffer[3 + i];
                        } else {
                            stdFlag = 1;
                            break;
                        }
                    }
                    if (stdFlag == 0) {
                        G_ERASE_FLASH(SERIAL_NUMBER_ADDR);
                        uint32_t buf;
                        memcpy(&buf, snNew, WORD_SIZE);
                        G_WRITE_FLASH(SERIAL_NUMBER_ADDR + WORD_SIZE, buf);
                        memcpy(&buf, snNew + WORD_SIZE, WORD_SIZE);
                        G_WRITE_FLASH(SERIAL_NUMBER_ADDR, buf);
                        memcpy(&snNew, snNew, 8);
                        srand(osKernelGetTickCount());
                        for (int i = 2; i < FLASH_PAGE_WORD_COUNT; ++i) {
                            G_WRITE_FLASH(SERIAL_NUMBER_ADDR + i * WORD_SIZE,
                                          rand());// NOLINT(cert-msc30-c, cert-msc50-cpp)
                        }

                        printf(SERIAL_FEEDBACK_INFO_SET_SERIAL_NUMBER, snNew[7], snNew[6],
                               snNew[5], snNew[4], snNew[3], snNew[2], snNew[1], snNew[0]);
                    } else {
                        printf(SERIAL_FEEDBACK_ERROR_ILLEGAL_SERIAL_NUMBER);
                    }
                    break;
                }
                case 'd': {
                    RTC_DATETIME_PRINT(SERIAL_FEEDBACK_INFO_GET_RTC_TIME);
                    break;
                }
                case '7': {
                    setFlashDPTR(47, 98);
                    BSP_W25Qx_Read((uint8_t *) &flashDataStruct, FLASH_SECTOR_ADDRESS(10), 0x1000);
                    for (int i = 0; i < 1024; ++i) {
                        printf("%d ", flashDataStruct.intAccess[i]);
                    }
                    printf("\r\n");
                    BSP_W25Qx_Read((uint8_t *) &flashDataStruct, FLASH_SECTOR_ADDRESS(11), 0x1000);
                    for (int i = 0; i < 1024; ++i) {
                        printf("%d ", flashDataStruct.intAccess[i]);
                    }
                    printf("\r\n");
                    break;
                }
                case '8': {
                    printf("R*EF22789445645678,wert1234,gfds4567,456e4563,gdfgd523,gfds4567,gfds4567,gfds4567\r\n");
                    printf("%lu\r\n", uxTaskGetStackHighWaterMark(serialProcessHandle));
                    taskTickCount = 0;
                    BSP_W25Qx_Erase_Chip();
                    break;
                }
                case 'T': {
                    getFlashDPTR();
                    char taskSetBuffer[14];
                    int stdFlag = 0;
                    for (int i = 0; i < 14; ++i) {
                        if (CHAR_NUMBER_CRITERION(RxMainBuffer[3 + i])) {
                            taskSetBuffer[i] = RxMainBuffer[3 + i];
                            stdFlag++;
                        } else {
                            break;
                        }
                    }
                    if (stdFlag == 14) {
                        int year = CHAR_TO_INT(taskSetBuffer[2]) * 10 +
                                   CHAR_TO_INT(taskSetBuffer[3]);
                        int month = CHAR_TO_INT(taskSetBuffer[4]) * 10 +
                                    CHAR_TO_INT(taskSetBuffer[5]);
                        int day = CHAR_TO_INT(taskSetBuffer[6]) * 10 +
                                  CHAR_TO_INT(taskSetBuffer[7]);
                        int hour = CHAR_TO_INT(taskSetBuffer[8]) * 10 +
                                   CHAR_TO_INT(taskSetBuffer[9]);
                        int minute = CHAR_TO_INT(taskSetBuffer[10]) * 10 +
                                     CHAR_TO_INT(taskSetBuffer[11]);
                        int second = CHAR_TO_INT(taskSetBuffer[12]) * 10 +
                                     CHAR_TO_INT(taskSetBuffer[13]);
                        if (DATETIME_CRITERION(year, month, day, hour, minute, second)) {
                            if (G_GET_BIT(statusReg, taskFlag)) {
                                for (int i = 0; i < 6; ++i) {
                                    for (int j = 0; j < 20; ++j) {
                                        taskDepthBuffer[i][j] = 0;
                                    }
                                    taskCountBuffer[i] = 0;
                                }
                                taskDataStruct.intAccess[0] = year;
                                taskDataStruct.intAccess[1] = month;
                                taskDataStruct.intAccess[2] = day;
                                taskDataStruct.intAccess[3] = hour;
                                taskDataStruct.intAccess[4] = minute;
                                taskDataStruct.intAccess[5] = second;
                                taskDataStruct.intAccess[6] = flashDataPointerEnd + 1;

                                int zMonth = month, zYear = year, zYearPrefix = year / 100;
                                if (month == 1 || month == 2) {
                                    zMonth += 12;
                                    zYear--;
                                }
                                int weekdayJudge = (zYear + zYear / 4 + zYearPrefix / 4 - 2 * zYearPrefix +
                                                    26 * (zMonth + 1) / 10 + day - 1) % 7;
                                RTC_DateTypeDef DateToUpdate = {0};
                                switch (weekdayJudge) {
                                    case 1: {
                                        DateToUpdate.WeekDay = RTC_WEEKDAY_MONDAY;
                                    }
                                    case 2: {
                                        DateToUpdate.WeekDay = RTC_WEEKDAY_TUESDAY;
                                    }
                                    case 3: {
                                        DateToUpdate.WeekDay = RTC_WEEKDAY_WEDNESDAY;
                                    }
                                    case 4: {
                                        DateToUpdate.WeekDay = RTC_WEEKDAY_THURSDAY;
                                    }
                                    case 5: {
                                        DateToUpdate.WeekDay = RTC_WEEKDAY_FRIDAY;
                                    }
                                    case 6: {
                                        DateToUpdate.WeekDay = RTC_WEEKDAY_SATURDAY;
                                    }
                                    case 0: {
                                        DateToUpdate.WeekDay = RTC_WEEKDAY_SUNDAY;
                                    }
                                    default: {
                                        DateToUpdate.WeekDay = RTC_WEEKDAY_MONDAY;
                                    }
                                }
                                DateToUpdate.Month = (month);
                                DateToUpdate.Date = (day);
                                DateToUpdate.Year = (year);
                                RTC_TimeTypeDef sTime = {0};
                                sTime.Hours = DECIMAL_TO_BCD(hour);
                                sTime.Minutes = DECIMAL_TO_BCD(minute);
                                sTime.Seconds = DECIMAL_TO_BCD(second);
                                HAL_RTC_SetDate(&hrtc, &DateToUpdate, RTC_FORMAT_BCD);
                                HAL_RTC_SetTime(&hrtc, &sTime, RTC_FORMAT_BCD);
                                printf(SERIAL_FEEDBACK_INFO_TASK_CREATE, taskDataStruct.intAccess[6]);
                                G_CLEAR_BIT(statusReg, taskFlag);
                            } else {
                                printf(SERIAL_FEEDBACK_ERROR_TASK_BUSY);
                            }
                        } else {
                            printf(SERIAL_FEEDBACK_ERROR_TASK_TIME_SYNC_FAIL);
                        }
                    } else {
                        printf(SERIAL_FEEDBACK_ERROR_TASK_TIME_SYNC_FAIL);
                    }
                    break;
                }
                case 'F': {
                    getFlashDPTR();
                    if (flashDataPointerStart == flashDataPointerEnd) {
                        printf(SERIAL_FEEDBACK_ERROR_FLASH__POINTER);
                    } else {
                        BSP_W25Qx_Read((uint8_t *) &flashDataStruct, FLASH_SECTOR_ADDRESS(flashDataPointerStart + 101),
                                       52);
                        printf(SERIAL_FEEDBACK_INFO_FETCH_DATA,
                               flashDataStruct.intAccess[0], flashDataStruct.intAccess[1], flashDataStruct.intAccess[2],
                               flashDataStruct.intAccess[3], flashDataStruct.intAccess[4], flashDataStruct.intAccess[5],
                               flashDataStruct.intAccess[6], flashDataStruct.wordAccess[7],
                               flashDataStruct.wordAccess[8], flashDataStruct.wordAccess[9],
                               flashDataStruct.wordAccess[10], flashDataStruct.wordAccess[11],
                               flashDataStruct.wordAccess[12]);

                    }
                    break;
                }
                case 'C': {
                    int stdFlag = 0;
                    for (int i = 0; i < 8; ++i) {
                        if (CHAR_ASCII_CRITERION(RxMainBuffer[3 + i])) {
                        } else {
                            stdFlag = 1;
                            break;
                        }
                    }
                    if (stdFlag == 0) {
                        getFlashDPTR();
                        if (flashDataPointerStart == flashDataPointerEnd) {
                            printf(SERIAL_FEEDBACK_ERROR_FLASH__POINTER);
                        } else {
                            int crc = CHAR_TO_INT(RxMainBuffer[3]) * 16 * 16 * 16 * 16 * 16 * 16 * 16 +
                                      CHAR_TO_INT(RxMainBuffer[4]) * 16 * 16 * 16 * 16 * 16 * 16 +
                                      CHAR_TO_INT(RxMainBuffer[5]) * 16 * 16 * 16 * 16 * 16 +
                                      CHAR_TO_INT(RxMainBuffer[6]) * 16 * 16 * 16 * 16 +
                                      CHAR_TO_INT(RxMainBuffer[7]) * 16 * 16 * 16 +
                                      CHAR_TO_INT(RxMainBuffer[8]) * 16 * 16 +
                                      CHAR_TO_INT(RxMainBuffer[9]) * 16 +
                                      CHAR_TO_INT(RxMainBuffer[10]);
                            BSP_W25Qx_Read((uint8_t *) &flashDataStruct,
                                           FLASH_SECTOR_ADDRESS(flashDataPointerStart + 101),
                                           52);
                            uint32_t Data_buffer[6] = {flashDataStruct.wordAccess[7], flashDataStruct.wordAccess[8],
                                                       flashDataStruct.wordAccess[9], flashDataStruct.wordAccess[10],
                                                       flashDataStruct.wordAccess[11], flashDataStruct.wordAccess[12]};
                            if (crc == HAL_CRC_Calculate(&hcrc, Data_buffer, 6)) {
                                printf(SERIAL_FEEDBACK_INFO_CRC_PASS, flashDataStruct.intAccess[0],
                                       flashDataStruct.intAccess[1], flashDataStruct.intAccess[2],
                                       flashDataStruct.intAccess[3], flashDataStruct.intAccess[4],
                                       flashDataStruct.intAccess[5]);
                                setFlashDPTR(flashDataPointerStart + 1, flashDataPointerEnd);
                            } else {
                                printf(SERIAL_FEEDBACK_ERROR_CRC_FAIL);
                            }
                        }
                    } else {
                        printf(SERIAL_FEEDBACK_ERROR_CRC_ILLEGAL);
                    }

                    break;
                }
                case 'E': {
                    setFlashDPTR(0, 0);
                    printf(SERIAL_FEEDBACK_INFO_FLASH_ERASE);
                    break;
                }
                case 'D': {
                    if (debugFlag == 0) {
                        debugFlag = 1;
                        switch (RxMainBuffer[3]) {
                            case '1': {
                                G_RELAY_CONTROL_REFRESH(1);
                                G_SMS_REFRESH(1);
                                currentChannel = 1;
                                HAL_Delay(100);
                                G_CONTROL_COMMAND_SEND();
                                break;
                            }
                            case '2': {
                                G_RELAY_CONTROL_REFRESH(2);
                                G_SMS_REFRESH(2);
                                currentChannel = 2;
                                HAL_Delay(100);
                                G_CONTROL_COMMAND_SEND();
                                break;
                            }
                            case '3': {
                                G_RELAY_CONTROL_REFRESH(3);
                                G_SMS_REFRESH(3);
                                currentChannel = 3;
                                HAL_Delay(100);
                                G_CONTROL_COMMAND_SEND();
                                break;
                            }
                            case '4': {
                                G_RELAY_CONTROL_REFRESH(4);
                                G_SMS_REFRESH(4);
                                currentChannel = 4;
                                HAL_Delay(100);
                                G_CONTROL_COMMAND_SEND();
                                break;
                            }
                            case '5': {
                                G_RELAY_CONTROL_REFRESH(5);
                                G_SMS_REFRESH(5);
                                currentChannel = 5;
                                HAL_Delay(100);
                                G_CONTROL_COMMAND_SEND();
                                break;
                            }
                            case '6': {
                                G_RELAY_CONTROL_REFRESH(6);
                                G_SMS_REFRESH(6);
                                currentChannel = 6;
                                HAL_Delay(100);
                                G_CONTROL_COMMAND_SEND();
                                break;
                            }
                            default: {
                                G_RELAY_CONTROL_REFRESH(10);
                                G_SMS_REFRESH(1);
                                currentChannel = 1;
                                break;
                            }
                        }
                        printf(SERIAL_FEEDBACK_INFO_DEBUG_ON);
                    } else {
                        debugFlag = 0;
                        G_RELAY_CONTROL_REFRESH(10);
                        G_SMS_REFRESH(1);
                        currentChannel = 1;
                        printf(SERIAL_FEEDBACK_INFO_DEBUG_OFF);
                    }
                    break;
                }
                case '2' : {
                    G_CONTROL_COMMAND_SEND();
                    break;
                }
                default: {
                    printf(SERIAL_FEEDBACK_ERROR_COMMAND_NOT_FOUND);
                }

            }
            G_SMS_REFRESH(currentChannel);
            HAL_UARTEx_ReceiveToIdle_DMA(&huart2, RxBuffer, RX_BUFFER_SIZE);
            __HAL_DMA_DISABLE_IT(&hdma_usart2_rx, DMA_IT_HT);
        }
    }
    /* USER CODE END serialCommandProcess */
}

/* heartbeatCallback function */
void heartbeatCallback(void *argument) {
    /* USER CODE BEGIN heartbeatCallback */
    UNUSED(argument);
    HAL_IWDG_Refresh(&hiwdg);

    HAL_UARTEx_ReceiveToIdle_DMA(&huart1, RxBufferSlave, RX_BUFFER_SIZE);
    __HAL_DMA_DISABLE_IT(&hdma_usart1_rx, DMA_IT_HT);
    HAL_UARTEx_ReceiveToIdle_DMA(&huart2, RxBuffer, RX_BUFFER_SIZE);
    __HAL_DMA_DISABLE_IT(&hdma_usart2_rx, DMA_IT_HT);

    HAL_RTC_GetTime(&hrtc, &currentTime, RTC_FORMAT_BCD);
    HAL_RTC_GetDate(&hrtc, &currentDate, RTC_FORMAT_BCD);

    if (!G_GET_BIT(statusReg, taskFlag)) {

        switch (taskTickCount) {
            case 0: {
                G_SET_BIT(statusReg, fathometerDataReadyFlag);
                currentChannel = 1;
                G_RELAY_CONTROL_REFRESH(currentChannel);
                G_SMS_REFRESH(currentChannel);
                break;
            }
            case 1: {
                G_CONTROL_COMMAND_SEND();
                break;
            }
            case 20: {
                if (G_GET_BIT(statusReg, fathometerDataReadyFlag) == 1) {
                    G_CONTROL_COMMAND_SEND();
                    G_SET_BIT(statusReg, fathometerStatFlag1);
                } else {
                    G_CLEAR_BIT(statusReg, fathometerStatFlag1);
                }
                break;
            }
            case 40: {
                G_SET_BIT(statusReg, fathometerDataReadyFlag);
                currentChannel = 2;
                G_RELAY_CONTROL_REFRESH(currentChannel);
                G_SMS_REFRESH(currentChannel);
                break;
            }
            case 41: {
                G_CONTROL_COMMAND_SEND();
                break;
            }
            case 60: {
                if (G_GET_BIT(statusReg, fathometerDataReadyFlag) == 1) {
                    G_CONTROL_COMMAND_SEND();
                    G_SET_BIT(statusReg, fathometerStatFlag2);
                } else {
                    G_CLEAR_BIT(statusReg, fathometerStatFlag2);
                }
                break;
            }
            case 80: {
                G_SET_BIT(statusReg, fathometerDataReadyFlag);
                currentChannel = 3;
                G_RELAY_CONTROL_REFRESH(currentChannel);
                G_SMS_REFRESH(currentChannel);
                break;
            }
            case 81: {
                G_CONTROL_COMMAND_SEND();
                break;
            }
            case 100: {
                if (G_GET_BIT(statusReg, fathometerDataReadyFlag) == 1) {
                    G_CONTROL_COMMAND_SEND();
                    G_SET_BIT(statusReg, fathometerStatFlag3);
                } else {
                    G_CLEAR_BIT(statusReg, fathometerStatFlag3);
                }
                break;
            }
            case 120: {
                G_SET_BIT(statusReg, fathometerDataReadyFlag);
                currentChannel = 4;
                G_RELAY_CONTROL_REFRESH(currentChannel);
                G_SMS_REFRESH(currentChannel);
                break;
            }
            case 121: {
                G_CONTROL_COMMAND_SEND();
                break;
            }
            case 140: {
                if (G_GET_BIT(statusReg, fathometerDataReadyFlag) == 1) {
                    G_CONTROL_COMMAND_SEND();
                    G_SET_BIT(statusReg, fathometerStatFlag4);
                } else {
                    G_CLEAR_BIT(statusReg, fathometerStatFlag4);
                }
                break;
            }
            case 160: {
                G_SET_BIT(statusReg, fathometerDataReadyFlag);
                currentChannel = 5;
                G_RELAY_CONTROL_REFRESH(currentChannel);
                G_SMS_REFRESH(currentChannel);
                break;
            }
            case 161: {
                G_CONTROL_COMMAND_SEND();
                break;
            }
            case 180: {
                if (G_GET_BIT(statusReg, fathometerDataReadyFlag) == 1) {
                    G_CONTROL_COMMAND_SEND();
                    G_SET_BIT(statusReg, fathometerStatFlag5);
                } else {
                    G_CLEAR_BIT(statusReg, fathometerStatFlag5);
                }
                break;
            }
            case 200: {
                G_SET_BIT(statusReg, fathometerDataReadyFlag);
                currentChannel = 6;
                G_RELAY_CONTROL_REFRESH(currentChannel);
                G_SMS_REFRESH(currentChannel);
                break;
            }
            case 201: {
                G_CONTROL_COMMAND_SEND();
                break;
            }
            case 220: {
                if (G_GET_BIT(statusReg, fathometerDataReadyFlag) == 1) {
                    G_CONTROL_COMMAND_SEND();
                    G_SET_BIT(statusReg, fathometerStatFlag6);
                } else {
                    G_CLEAR_BIT(statusReg, fathometerStatFlag6);
                }
                break;
            }
            default: {
                if (taskTickCount >= 240) {
                    G_RELAY_CONTROL_REFRESH(10);
                    taskTickCount = -1;
                    G_SET_BIT(statusReg, taskFlag);
                    for (int i = 0; i < 6; ++i) {
                        float sum = 0;
                        for (int j = 0; j < 20; ++j) {
                            sum += taskDepthBuffer[i][j];
                        }
                        taskDataStruct.floatAccess[7 + i] = taskCountBuffer[i] == 0 ?
                                                            0 : sum / (float) (taskCountBuffer[i] > 20 ? 20
                                                                                                       : taskCountBuffer[i]);
                    }
//                    printf("%d %d %d %d %d %d | %d | %.2f %.2f %.2f %.2f %.2f %.2f\r\n", taskDataStruct.intAccess[0],
//                           taskDataStruct.intAccess[1], taskDataStruct.intAccess[2], taskDataStruct.intAccess[3],
//                           taskDataStruct.intAccess[4], taskDataStruct.intAccess[5], taskDataStruct.intAccess[6],
//                           taskDataStruct.floatAccess[7], taskDataStruct.floatAccess[8], taskDataStruct.floatAccess[9],
//                           taskDataStruct.floatAccess[10], taskDataStruct.floatAccess[11],
//                           taskDataStruct.floatAccess[12]);
                    BSP_W25Qx_Erase_Block(FLASH_SECTOR_ADDRESS(taskDataStruct.intAccess[6] + 100));
                    BSP_W25Qx_Write((uint8_t *) &taskDataStruct,
                                    FLASH_SECTOR_ADDRESS(taskDataStruct.intAccess[6] + 100),
                                    52);
                    setFlashDPTR(flashDataPointerStart, taskDataStruct.intAccess[6]);
                }
            }
        }
        taskTickCount++;
    }

    /* USER CODE END heartbeatCallback */
}

/* USER CODE BEGIN Application */
void HAL_UARTEx_RxEventCallback(UART_HandleTypeDef *huart, uint16_t Size) {
    if (huart->Instance == USART2) {
        if (Size == RX_BUFFER_SIZE && RxBuffer[Size - 1] != 0x0A) {
            printf(SERIAL_FEEDBACK_ERROR_COMMAND_OVERFLOW);
            HAL_UARTEx_ReceiveToIdle_DMA(&huart2, RxBuffer, RX_BUFFER_SIZE);
            __HAL_DMA_DISABLE_IT(&hdma_usart2_rx, DMA_IT_HT);
        } else {
            memcpy((uint8_t *) RxMainBuffer, RxBuffer, Size);
            if (RxBuffer[0] == 0x47 && RxBuffer[1] == 0x2B && RxBuffer[Size - 2] == 0x0D &&
                RxBuffer[Size - 1] == 0x0A) {
                G_SMS_REFRESH(7);
                osEventFlagsSet(serialCommandEventHandle, SERIAL_EVENT_FLAG);
            } else {
                HAL_UARTEx_ReceiveToIdle_DMA(&huart2, RxBuffer, RX_BUFFER_SIZE);
                __HAL_DMA_DISABLE_IT(&hdma_usart2_rx, DMA_IT_HT);
            }
        }
    } else if (huart->Instance == USART1) {
        G_SMS_REFRESH(8);
        memcpy((uint8_t *) RxMainBufferSlave, RxBufferSlave, Size);
        uint16_t SizeBackup = Size;
//        for (int i = 0; i < Size; ++i) {
//            HAL_UART_Transmit(&huart2, (uint8_t *) &RxMainBufferSlave[i], 1, 10);
//        }

        int dollarFlag = -1, crFlag = -1, lfFlag = -1, processFlag = 0;
        for (int i = 0; i < Size; ++i) {
            if (RxMainBufferSlave[i] == 0x24) {
                dollarFlag = i;
                crFlag = -1;
                lfFlag = -1;
            } else if (RxMainBufferSlave[i] == 0x0D) {
                crFlag = i;
            } else if (RxMainBufferSlave[i] == 0x0A) {
                lfFlag = i;
            }
            if (dollarFlag != -1 && crFlag != -1 && lfFlag != -1) {
                break;
            }
        }
        if (dollarFlag != -1 && crFlag != -1 && lfFlag != -1 && lfFlag - crFlag == 1) {
            if (dollarFlag != 0) {
                for (int i = 0; i < Size - dollarFlag; ++i) {
                    RxMainBufferSlave[i] = RxMainBufferSlave[i + dollarFlag];
                }
            }
            Size = lfFlag - dollarFlag + 1;
            if (RxMainBufferSlave[Size - 5] == 0x2A && RxMainBufferSlave[Size - 6] == 0x2C &&
                RxMainBufferSlave[Size - 8] == 0x2C) {
                if (RxMainBufferSlave[Size - 7] == 0x20) {
                    char checkSum = RxMainBufferSlave[1];
                    for (int i = 0; i < Size - 6; ++i) {
                        checkSum = checkSum ^ RxMainBufferSlave[2 + i];
                    }
                    if (CHAR_TO_INT(RxMainBufferSlave[Size - 3]) +
                        CHAR_TO_INT(RxMainBufferSlave[Size - 4]) * 16 == checkSum) {
                        int depthPointer = 0;
                        float depth = 0;
                        for (int i = 0; i < Size; ++i) {
                            if (RxMainBufferSlave[i] == 0x2E) {
                                depthPointer = i;
                                break;
                            }
                        }
                        for (int i = 1; i < depthPointer; ++i) {
                            depth += (float) (CHAR_TO_INT(RxMainBufferSlave[i]) * pow(10, depthPointer - i - 1));
                        }
                        for (int i = depthPointer + 1; i < Size - 8; ++i) {
                            depth += (float) (CHAR_TO_INT(RxMainBufferSlave[i]) * pow(10, depthPointer - i));
                        }
                        taskCountBuffer[currentChannel - 1]++;
                        for (int i = 0; i < 19; ++i) {
                            taskDepthBuffer[currentChannel - 1][i] = taskDepthBuffer[currentChannel - 1][i + 1];
                        }
                        taskDepthBuffer[currentChannel - 1][19] = depth;
                        processFlag = 1;
                        if (debugFlag == 1) {
                            printf("[Debug Calculate Depth]%.2f[EndDebug]\r\n", depth);
                        }
                        G_CLEAR_BIT(statusReg, fathometerDataReadyFlag);
                    }
                }
            }
        }
        if (processFlag == 0 && debugFlag == 1) {
            printf("[Debug Serial Receive]");
            for (int i = 0; i < SizeBackup; ++i) {
                printf("%c", RxMainBufferSlave[i]);
            }
            printf("[EndDebug]\r\n");
        }
        G_SMS_REFRESH(currentChannel);
        HAL_UARTEx_ReceiveToIdle_DMA(&huart1, RxBufferSlave, RX_BUFFER_SIZE);
        __HAL_DMA_DISABLE_IT(&hdma_usart1_rx, DMA_IT_HT);
    }
}

void readUniqueID(volatile uint32_t *IDArrayPtr) {
    volatile uint32_t Addr = 0x20000006;
    Addr -= 0x800;
    IDArrayPtr[0] = G_READ_FLASH(Addr -= 0x1E);
    IDArrayPtr[1] = G_READ_FLASH(Addr += WORD_SIZE);
    IDArrayPtr[2] = G_READ_FLASH(Addr += WORD_SIZE);
}

void intellectualPropertyProtection(void) {
    readUniqueID((volatile uint32_t *) UID);
    volatile uint32_t baseAddr = IPP_BASE_ADDRESS;
    if (G_READ_FLASH(baseAddr -= 0x17F80804) == IPP_CRITERION_1) {
        uint32_t ippData = G_READ_FLASH(baseAddr += WORD_SIZE);
        ippData &= G_READ_FLASH(baseAddr += WORD_SIZE);
        if ((ippData |= G_READ_FLASH(baseAddr += WORD_SIZE)) == IPP_CRITERION_2) {
            intellectualPropertyProtectionSet();
        }
    }
    baseAddr = IPP_BASE_ADDRESS;
    if (G_READ_FLASH(baseAddr -= 0x17F807E0) == (UID[0] & (UID[1] | UID[2]))) {
        G_CLEAR_BIT(statusReg, ippFlag);
    } else {
        G_SET_BIT(statusReg, ippFlag);
        printf(SERIAL_FEEDBACK_ERROR_IPP_TRIGGERED);
        printf(SERIAL_FEEDBACK_WARNING_IPP_LEGAL_NOTICE);
        if (osThreadTerminate(serialProcessHandle) == osOK) {
            printf(SERIAL_FEEDBACK_INFO_SHUTDOWN_SERIAL);
        }
        if (osTimerStop(heartbeatTimerHandle) == osOK) {
            printf(SERIAL_FEEDBACK_INFO_SHUTDOWN_HEARTBEAT);
        }
        printf(SERIAL_FEEDBACK_INFO_CONTACT_INFO);

        int dotCount = 0;
        while (1) {
            osDelay(100);
            HAL_IWDG_Refresh(&hiwdg);
            printf(".");
            fflush(stdout);
            dotCount++;
            if (dotCount == 10) {
                //TODO: Self-Destruct in Bootloader
                for (int i = 0; i < 255; ++i) {
                    G_ERASE_FLASH(FLASH_END_ADDRESS - (i + 1) * FLASH_PAGE_SIZE);
                    HAL_IWDG_Refresh(&hiwdg);
                }
            }
        }
    }
}

void intellectualPropertyProtectionSet(void) {
    volatile uint32_t baseAddr = IPP_BASE_ADDRESS;
    baseAddr -= 0x17F807E0;
    G_ERASE_FLASH(baseAddr);
    G_WRITE_FLASH(baseAddr, UID[0] & (UID[1] | UID[2]));

    srand(osKernelGetTickCount());
    for (int i = 1; i < IPP_BLANK_AFTER; ++i) {
        G_WRITE_FLASH(baseAddr + i * WORD_SIZE, rand());// NOLINT(cert-msc30-c, cert-msc50-cpp)
    }
    for (int i = 1; i < IPP_BLANK_BEFORE; ++i) {
        G_WRITE_FLASH(baseAddr - i * WORD_SIZE, rand());// NOLINT(cert-msc30-c, cert-msc50-cpp)
    }

    G_CLEAR_BIT(statusReg, ippFlag);
    printf(SERIAL_FEEDBACK_INFO_IPP_SET);

//    FLASH_OBProgramInitTypeDef OBInit;
//    __HAL_FLASH_PREFETCH_BUFFER_DISABLE();
//    HAL_FLASHEx_OBGetConfig(&OBInit);
//    if (OBInit.RDPLevel == OB_RDP_LEVEL_0) {
//        printf("[Info] Factory Mode: Readout Protection is now set, RDP option byte programmed\r\n");
//        for (int i = 0; i < 3; ++i) {
//            printf("[Warning] Factory Mode: Please restart device......\r\n");
//        }
//        printf("\r\n");
//
//        OBInit.OptionType = OPTIONBYTE_RDP;
//        OBInit.RDPLevel = OB_RDP_LEVEL_1;
//        HAL_FLASH_Unlock();
//        HAL_FLASH_OB_Unlock();
//        HAL_FLASHEx_OBProgram(&OBInit);
//        HAL_FLASH_OB_Launch();
//        HAL_FLASH_OB_Lock();
//        HAL_FLASH_Lock();
//    }
//    __HAL_FLASH_PREFETCH_BUFFER_ENABLE();

    G_SYSTEM_RESET();
}

void peripheralInit(void) {

    //Firmware Version
    printf(SERIAL_FEEDBACK_INFO_GET_FIRMWARE_VERSION, "v1.0.0");

    //Serial Number
    G_SN_PRINT(0);
    HAL_GPIO_WritePin(RS485_232_GPIO_Port, RS485_232_Pin, GPIO_PIN_SET);
    HAL_GPIO_WritePin(DE485_GPIO_Port, DE485_Pin, GPIO_PIN_RESET);

    //Baud Rate
    printf(SERIAL_FEEDBACK_INFO_GET_BAUD_RATE);

    //SMS/POST Init
    for (int i = 1; i < 9; i++) {
        G_SMS_REFRESH(i);
        HAL_Delay(20);
    }
    for (int i = 7; i > 0; i--) {
        G_SMS_REFRESH(i);
        HAL_Delay(20);
    }

    //RTC Init
    if (G_READ_FLASH(RTC_INIT_FLAG_ADDR) == RTC_INIT_FLAG_DATA) {
        HAL_RTC_GetTime(&hrtc, &currentTime, RTC_FORMAT_BCD);
        HAL_RTC_GetDate(&hrtc, &currentDate, RTC_FORMAT_BCD);
        RTC_DATETIME_PRINT(SERIAL_FEEDBACK_INFO_RTC_INIT);
    }

    //ADC Init
    HAL_ADCEx_Calibration_Start(&hadc1);
    HAL_ADC_Start_DMA(&hadc1, (uint32_t *) &AD_DMA_BUFFER, 2);
    HAL_Delay(10);
    printf(SERIAL_FEEDBACK_INFO_ADC_INIT, GET_SYSTEM_VOLTAGE(AD_DMA_BUFFER[1]), GET_MAIN_VOLTAGE(AD_DMA_BUFFER[0]));

    //W25Q64 Init
    uint8_t ID[4];
    BSP_W25Qx_Init();
    BSP_W25Qx_Read_ID(ID);
    if ((ID[0] == 0xEF) && (ID[1] == 0x16)) {
        printf(SERIAL_FEEDBACK_INFO_FLASH_INIT);
    }
    getFlashDPTR();
    G_CLEAR_BIT(statusReg, flashDataPointerFlag);
    printf(SERIAL_FEEDBACK_INFO_RECORDS_ALERT, flashDataPointerEnd - flashDataPointerStart);

    //Serial Terminal Init
    while (HAL_UARTEx_ReceiveToIdle_DMA(&huart2, RxBuffer, RX_BUFFER_SIZE) != HAL_OK);
    __HAL_DMA_DISABLE_IT(&hdma_usart2_rx, DMA_IT_HT);
    while (HAL_UARTEx_ReceiveToIdle_DMA(&huart1, RxBufferSlave, RX_BUFFER_SIZE) != HAL_OK);
    __HAL_DMA_DISABLE_IT(&hdma_usart1_rx, DMA_IT_HT);

    G_CLEAR_BIT(statusReg, voltageFlag);
}

void getFlashDPTR(void) {
    BSP_W25Qx_Read((uint8_t *) &flashDataStruct, FLASH_SECTOR_ADDRESS(10), 0x1000);
    for (int i = 0x3FF; i >= 0; --i) {
        if (flashDataStruct.wordAccess[i] != 0xFFFFFFFF) {
            flashDataPointerStart = flashDataStruct.intAccess[i];
            break;
        }
        if (i == 0) {
            printf(SERIAL_FEEDBACK_INFO_FLASH_D_PTR_START_INIT);
            flashDataPointerStart = 0;
            flashDataStruct.intAccess[0] = 0;
            BSP_W25Qx_Write((uint8_t *) &flashDataStruct, FLASH_SECTOR_ADDRESS(10), 0x4);
        }
    }
    BSP_W25Qx_Read((uint8_t *) &flashDataStruct, FLASH_SECTOR_ADDRESS(11), 0x1000);
    for (int i = 0x3FF; i >= 0; --i) {
        if (flashDataStruct.wordAccess[i] != 0xFFFFFFFF) {
            flashDataPointerEnd = flashDataStruct.intAccess[i];
            break;
        }
        if (i == 0) {
            printf(SERIAL_FEEDBACK_INFO_FLASH_D_PTR_END_INIT);
            flashDataPointerEnd = 0;
            flashDataStruct.intAccess[0] = 0;
            BSP_W25Qx_Write((uint8_t *) &flashDataStruct, FLASH_SECTOR_ADDRESS(11), 0x4);
        }
    }
}

void setFlashDPTR(int start, int end) {
    BSP_W25Qx_Read((uint8_t *) &flashDataStruct, FLASH_SECTOR_ADDRESS(10), 0x1000);
    for (int i = 0; i < 0x400; ++i) {
        if (flashDataStruct.wordAccess[i] == 0xFFFFFFFF) {
            flashDataStruct.intAccess[0] = start;
            BSP_W25Qx_Write((uint8_t *) &flashDataStruct, FLASH_SECTOR_ADDRESS(10) + i * 4, 0x4);
            break;
        }
        if (i == 0x3FF) {
            BSP_W25Qx_Erase_Block(FLASH_SECTOR_ADDRESS(10));
            flashDataStruct.intAccess[0] = start;
            BSP_W25Qx_Write((uint8_t *) &flashDataStruct, FLASH_SECTOR_ADDRESS(10), 0x4);
        }
    }

    BSP_W25Qx_Read((uint8_t *) &flashDataStruct, FLASH_SECTOR_ADDRESS(11), 0x1000);
    for (int i = 0; i < 0x400; ++i) {
        if (flashDataStruct.wordAccess[i] == 0xFFFFFFFF) {
            flashDataStruct.intAccess[0] = end;
            BSP_W25Qx_Write((uint8_t *) &flashDataStruct, FLASH_SECTOR_ADDRESS(11) + i * 4, 0x4);
            break;
        }
        if (i == 0x3FF) {
            BSP_W25Qx_Erase_Block(FLASH_SECTOR_ADDRESS(11));
            flashDataStruct.intAccess[0] = end;
            BSP_W25Qx_Write((uint8_t *) &flashDataStruct, FLASH_SECTOR_ADDRESS(11), 0x4);
        }
    }
}

void G_CONTROL_COMMAND_SEND(void){
    HAL_UART_DMAStop(&huart1);
    uint8_t test[8] = {'$', 'R', 'u', 'n', '=', '1', '\r', '\n'};
    HAL_GPIO_WritePin(DE485_GPIO_Port, DE485_Pin, GPIO_PIN_SET);
    HAL_Delay(1);
    HAL_UART_Transmit(&huart1, (uint8_t *) &test, 8, 10);
    HAL_Delay(10);
    HAL_GPIO_WritePin(DE485_GPIO_Port, DE485_Pin, GPIO_PIN_RESET);
    while (HAL_UARTEx_ReceiveToIdle_DMA(&huart1, RxBufferSlave, RX_BUFFER_SIZE) != HAL_OK);
    __HAL_DMA_DISABLE_IT(&hdma_usart1_rx, DMA_IT_HT);
}
/* USER CODE END Application */
